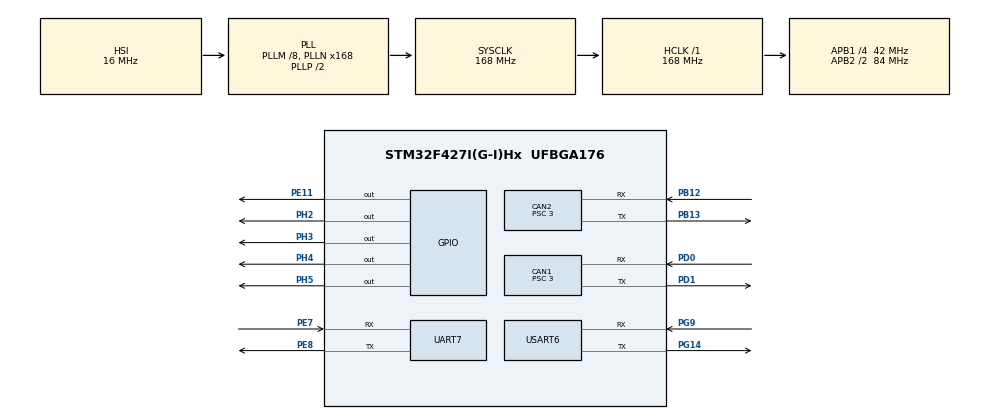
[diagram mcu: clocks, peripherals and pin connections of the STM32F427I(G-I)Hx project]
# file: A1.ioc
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CAN1.BS1=CAN_BS1_6TQ
CAN1.BS2=CAN_BS2_7TQ
CAN1.CalculateBaudRate=1000000
CAN1.CalculateTimeBit=999.99
CAN1.CalculateTimeQuantum=71.42857142857143
CAN1.Prescaler=3
CAN2.BS1=CAN_BS1_6TQ
CAN2.BS2=CAN_BS2_7TQ
CAN2.CalculateBaudRate=1000000
CAN2.CalculateTimeBit=999.99
CAN2.CalculateTimeQuantum=71.42857142857143
CAN2.Prescaler=3
Dma.Request0=USART6_RX
Dma.Request1=USART6_TX
Dma.USART6_RX.0.Direction=DMA_PERIPH_TO_MEMORY
Dma.USART6_RX.0.FIFOMode=DMA_FIFOMODE_DISABLE
Dma.USART6_RX.0.Instance=DMA2_Stream1
Dma.USART6_RX.0.MemDataAlignment=DMA_MDATAALIGN_BYTE
Dma.USART6_RX.0.MemInc=DMA_MINC_ENABLE
Dma.USART6_RX.0.Mode=DMA_NORMAL
Dma.USART6_RX.0.PeriphDataAlignment=DMA_PDATAALIGN_BYTE
Dma.USART6_RX.0.PeriphInc=DMA_PINC_DISABLE
Dma.USART6_RX.0.Priority=DMA_PRIORITY_LOW
Dma.USART6_TX.1.Direction=DMA_MEMORY_TO_PERIPH
Dma.USART6_TX.1.FIFOMode=DMA_FIFOMODE_DISABLE
Dma.USART6_TX.1.Instance=DMA2_Stream6
Dma.USART6_TX.1.MemDataAlignment=DMA_MDATAALIGN_BYTE
Dma.USART6_TX.1.MemInc=DMA_MINC_ENABLE
Dma.USART6_TX.1.Mode=DMA_NORMAL
Dma.USART6_TX.1.PeriphDataAlignment=DMA_PDATAALIGN_BYTE
Dma.USART6_TX.1.PeriphInc=DMA_PINC_DISABLE
Dma.USART6_TX.1.Priority=DMA_PRIORITY_LOW
Mcu.Family=STM32F4
Mcu.Name=STM32F427I(G-I)Hx
Mcu.Package=UFBGA176
NVIC.CAN1_RX0_IRQn=true\:0\:0\:false\:false\:true\:true\:true
NVIC.CAN1_TX_IRQn=true\:0\:0\:false\:false\:true\:true\:true
NVIC.CAN2_RX0_IRQn=true\:0\:0\:false\:false\:true\:true\:true
NVIC.CAN2_TX_IRQn=true\:0\:0\:false\:false\:true\:true\:true
NVIC.DMA2_Stream1_IRQn=true\:0\:0\:false\:false\:true\:false\:true
NVIC.DMA2_Stream6_IRQn=true\:0\:0\:false\:false\:true\:false\:true
NVIC.PriorityGroup=NVIC_PRIORITYGROUP_4
NVIC.USART6_IRQn=true\:0\:0\:false\:false\:true\:true\:true
PA13.Mode=JTAG_5_pins
PA13.Signal=SYS_JTMS-SWDIO
PA14.Mode=JTAG_5_pins
PA14.Signal=SYS_JTCK-SWCLK
PA15.Mode=JTAG_5_pins
PA15.Signal=SYS_JTDI
PB12.Mode=CAN_Activate
PB12.Signal=CAN2_RX
PB13.Mode=CAN_Activate
PB13.Signal=CAN2_TX
PB3.Mode=JTAG_5_pins
PB3.Signal=SYS_JTDO-SWO
PB4.Mode=JTAG_5_pins
PB4.Signal=SYS_JTRST
PD0.Mode=CAN_Activate
PD0.Signal=CAN1_RX
PD1.Mode=CAN_Activate
PD1.Signal=CAN1_TX
PE11.PinState=GPIO_PIN_RESET
PE11.Signal=GPIO_Output
PE7.Mode=Asynchronous
PE7.Signal=UART7_RX
PE8.Mode=Asynchronous
PE8.Signal=UART7_TX
PG14.Mode=Asynchronous
PG14.Signal=USART6_TX
PG9.Mode=Asynchronous
PG9.Signal=USART6_RX
PH0/OSC_IN.Mode=HSE-External-Oscillator
PH0/OSC_IN.Signal=RCC_OSC_IN
PH1/OSC_OUT.Mode=HSE-External-Oscillator
PH1/OSC_OUT.Signal=RCC_OSC_OUT
PH2.PinState=GPIO_PIN_SET
PH2.Signal=GPIO_Output
PH3.PinState=GPIO_PIN_SET
PH3.Signal=GPIO_Output
PH4.PinState=GPIO_PIN_SET
PH4.Signal=GPIO_Output
PH5.PinState=GPIO_PIN_SET
PH5.Signal=GPIO_Output
ProjectManager.HeapSize=0x200
ProjectManager.StackSize=0x400
ProjectManager.TargetToolchain=MDK-ARM V5.32
RCC.48MHZClocksFreq_Value=84000000
RCC.AHBFreq_Value=168000000
RCC.APB1CLKDivider=RCC_HCLK_DIV4
RCC.APB1Freq_Value=42000000
RCC.APB1TimFreq_Value=84000000
RCC.APB2CLKDivider=RCC_HCLK_DIV2
RCC.APB2Freq_Value=84000000
RCC.APB2TimFreq_Value=168000000
RCC.CortexFreq_Value=168000000
RCC.HCLKFreq_Value=168000000
RCC.HSE_VALUE=12000000
RCC.HSI_VALUE=16000000
RCC.LSE_VALUE=32768
RCC.PLLM=8
RCC.PLLN=168
RCC.SYSCLKFreq_VALUE=168000000
RCC.SYSCLKSource=RCC_SYSCLKSOURCE_PLLCLK
RCC.VCOOutputFreq_Value=336000000
UART7.VirtualMode=Asynchronous
USART6.VirtualMode=VM_ASYNC
board=custom

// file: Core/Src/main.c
/* USER CODE BEGIN Header */
/**
  ******************************************************************************
  * @file           : main.c
  * @brief          : Main program body
  ******************************************************************************
  * @attention
  *
  * <h2><center>&copy; Copyright (c) 2022 STMicroelectronics.
  * All rights reserved.</center></h2>
  *
  * This software component is licensed by ST under BSD 3-Clause license,
  * the "License"; You may not use this file except in compliance with the
  * License. You may obtain a copy of the License at:
  *                        opensource.org/licenses/BSD-3-Clause
  *
  ******************************************************************************
  */
/* USER CODE END Header */
#include "main.h"
#include "can.h"
#include "dma.h"
#include "usart.h"
#include "gpio.h"

void SystemClock_Config(void);

int main(void)
{

  /* MCU Configuration--------------------------------------------------------*/

  /* Reset of all peripherals, Initializes the Flash interface and the Systick. */
  HAL_Init();

  /* Configure the system clock */
  SystemClock_Config();

  /* Initialize all configured peripherals */
  MX_GPIO_Init();
  MX_DMA_Init();
  MX_CAN1_Init();
  MX_CAN2_Init();
  MX_USART6_UART_Init();
  MX_UART7_Init();
  /* USER CODE BEGIN 2 */
  state_set();
  /* USER CODE END 2 */

  /* Infinite loop */
  while (1)
  {

  }
}

void SystemClock_Config(void)
{
  RCC_OscInitTypeDef RCC_OscInitStruct = {0};
  RCC_ClkInitTypeDef RCC_ClkInitStruct = {0};

  /** Configure the main internal regulator output voltage
  */
  __HAL_RCC_PWR_CLK_ENABLE();
  __HAL_PWR_VOLTAGESCALING_CONFIG(PWR_REGULATOR_VOLTAGE_SCALE1);
  /** Initializes the RCC Oscillators according to the specified parameters
  * in the RCC_OscInitTypeDef structure.
  */
  RCC_OscInitStruct.OscillatorType = RCC_OSCILLATORTYPE_HSI;
  RCC_OscInitStruct.HSIState = RCC_HSI_ON;
  RCC_OscInitStruct.HSICalibrationValue = RCC_HSICALIBRATION_DEFAULT;
  RCC_OscInitStruct.PLL.PLLState = RCC_PLL_ON;
  RCC_OscInitStruct.PLL.PLLSource = RCC_PLLSOURCE_HSI;
  RCC_OscInitStruct.PLL.PLLM = 8;
  RCC_OscInitStruct.PLL.PLLN = 168;
  RCC_OscInitStruct.PLL.PLLP = RCC_PLLP_DIV2;
  RCC_OscInitStruct.PLL.PLLQ = 4;
  if (HAL_RCC_OscConfig(&RCC_OscInitStruct) != HAL_OK)
  {
    Error_Handler();
  }
  /** Initializes the CPU, AHB and APB buses clocks
  */
  RCC_ClkInitStruct.ClockType = RCC_CLOCKTYPE_HCLK|RCC_CLOCKTYPE_SYSCLK
                              |RCC_CLOCKTYPE_PCLK1|RCC_CLOCKTYPE_PCLK2;
  RCC_ClkInitStruct.SYSCLKSource = RCC_SYSCLKSOURCE_PLLCLK;
  RCC_ClkInitStruct.AHBCLKDivider = RCC_SYSCLK_DIV1;
  RCC_ClkInitStruct.APB1CLKDivider = RCC_HCLK_DIV4;
  RCC_ClkInitStruct.APB2CLKDivider = RCC_HCLK_DIV2;

  if (HAL_RCC_ClockConfig(&RCC_ClkInitStruct, FLASH_LATENCY_5) != HAL_OK)
  {
    Error_Handler();
  }
}

void Error_Handler(void)
{
  __disable_irq();
  while (1)
  {
  }
}

/************************ (C) COPYRIGHT STMicroelectronics *****END OF FILE****/
